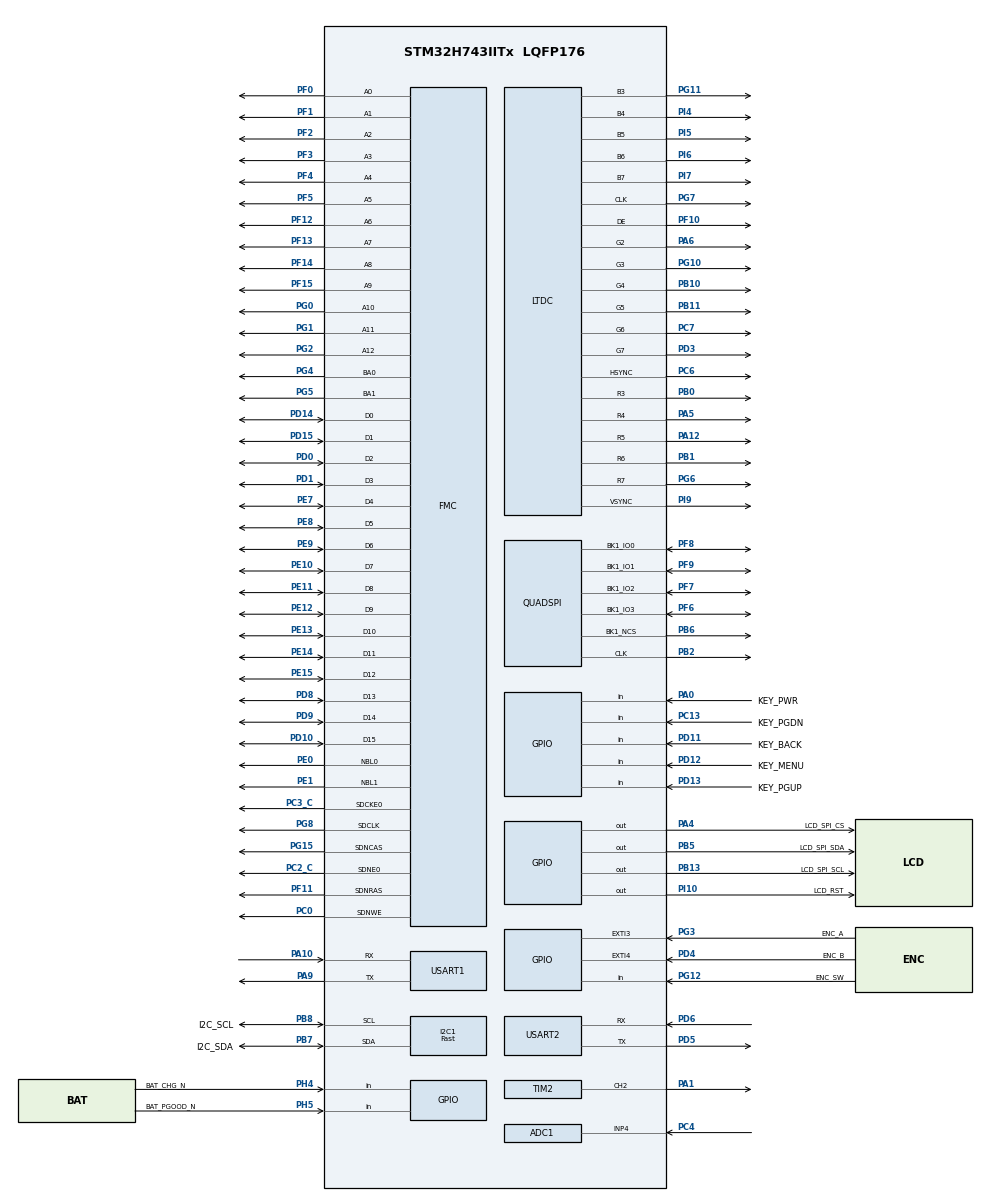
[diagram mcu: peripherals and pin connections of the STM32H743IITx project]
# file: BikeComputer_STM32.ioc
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ADC1.Channel-0\#ChannelRegularConversion=ADC_CHANNEL_4
ADC1.ClockPrescaler=ADC_CLOCK_ASYNC_DIV4
ADC1.NbrOfConversionFlag=1
ADC1.OffsetNumber-0\#ChannelRegularConversion=ADC_OFFSET_NONE
ADC1.OffsetSignedSaturation-0\#ChannelRegularConversion=DISABLE
ADC1.Rank-0\#ChannelRegularConversion=1
ADC1.SamplingTime-0\#ChannelRegularConversion=ADC_SAMPLETIME_387CYCLES_5
ADC1.master=1
CORTEX_M7.AccessPermission_S-Cortex_Memory_Protection_Unit_Region1_Settings_S=MPU_REGION_FULL_ACCESS
CORTEX_M7.AccessPermission_S-Cortex_Memory_Protection_Unit_Region2_Settings_S=MPU_REGION_FULL_ACCESS
CORTEX_M7.AccessPermission_S-Cortex_Memory_Protection_Unit_Region3_Settings_S=MPU_REGION_PRIV_RO_URO
CORTEX_M7.AccessPermission_Spec=MPU_REGION_NO_ACCESS
CORTEX_M7.BaseAddress_S-Cortex_Memory_Protection_Unit_Region1_Settings_S=0xC0000000
CORTEX_M7.BaseAddress_S-Cortex_Memory_Protection_Unit_Region2_Settings_S=0xC0000000
CORTEX_M7.BaseAddress_S-Cortex_Memory_Protection_Unit_Region3_Settings_S=0x90000000
CORTEX_M7.BaseAddress_Spec=0x00000000
CORTEX_M7.CPU_DCache=Enabled
CORTEX_M7.CPU_ICache=Enabled
CORTEX_M7.DisableExec_S-Cortex_Memory_Protection_Unit_Region1_Settings_S=MPU_INSTRUCTION_ACCESS_DISABLE
CORTEX_M7.DisableExec_S-Cortex_Memory_Protection_Unit_Region2_Settings_S=MPU_INSTRUCTION_ACCESS_DISABLE
CORTEX_M7.DisableExec_S-Cortex_Memory_Protection_Unit_Region3_Settings_S=MPU_INSTRUCTION_ACCESS_DISABLE
CORTEX_M7.Enable_S-Cortex_Memory_Protection_Unit_Region1_Settings_S=MPU_REGION_ENABLE
CORTEX_M7.Enable_S-Cortex_Memory_Protection_Unit_Region2_Settings_S=MPU_REGION_ENABLE
CORTEX_M7.Enable_S-Cortex_Memory_Protection_Unit_Region3_Settings_S=MPU_REGION_ENABLE
CORTEX_M7.IsBufferable_S-Cortex_Memory_Protection_Unit_Region1_Settings_S=MPU_ACCESS_BUFFERABLE
CORTEX_M7.IsBufferable_Spec=MPU_ACCESS_NOT_BUFFERABLE
CORTEX_M7.IsCacheable_S-Cortex_Memory_Protection_Unit_Region1_Settings_S=MPU_ACCESS_CACHEABLE
CORTEX_M7.IsCacheable_Spec=MPU_ACCESS_NOT_CACHEABLE
CORTEX_M7.IsShareable_Spec=MPU_ACCESS_SHAREABLE
CORTEX_M7.Size_S-Cortex_Memory_Protection_Unit_Region1_Settings_S=MPU_REGION_SIZE_32MB
CORTEX_M7.Size_S-Cortex_Memory_Protection_Unit_Region2_Settings_S=MPU_REGION_SIZE_2MB
CORTEX_M7.Size_S-Cortex_Memory_Protection_Unit_Region3_Settings_S=MPU_REGION_SIZE_16MB
CORTEX_M7.Size_Spec=MPU_REGION_SIZE_4GB
CORTEX_M7.SubRegionDisable_Spec=0x87
CORTEX_M7.TypeExtField_S-Cortex_Memory_Protection_Unit_Region2_Settings_S=MPU_TEX_LEVEL1
CORTEX_M7.TypeExtField_S-Cortex_Memory_Protection_Unit_Region3_Settings_S=MPU_TEX_LEVEL1
CORTEX_M7.default_mode_Activation=1
DMA2D.ColorMode=DMA2D_OUTPUT_RGB565
Dma.Request0=USART2_RX
Dma.USART2_RX.0.Direction=DMA_PERIPH_TO_MEMORY
Dma.USART2_RX.0.EventEnable=DISABLE
Dma.USART2_RX.0.FIFOMode=DMA_FIFOMODE_DISABLE
Dma.USART2_RX.0.Instance=DMA1_Stream0
Dma.USART2_RX.0.MemDataAlignment=DMA_MDATAALIGN_BYTE
Dma.USART2_RX.0.MemInc=DMA_MINC_ENABLE
Dma.USART2_RX.0.Mode=DMA_CIRCULAR
Dma.USART2_RX.0.PeriphDataAlignment=DMA_PDATAALIGN_BYTE
Dma.USART2_RX.0.PeriphInc=DMA_PINC_DISABLE
Dma.USART2_RX.0.Polarity=HAL_DMAMUX_REQ_GEN_RISING
Dma.USART2_RX.0.Priority=DMA_PRIORITY_HIGH
Dma.USART2_RX.0.RequestNumber=1
Dma.USART2_RX.0.SignalID=NONE
Dma.USART2_RX.0.SyncEnable=DISABLE
Dma.USART2_RX.0.SyncPolarity=HAL_DMAMUX_SYNC_NO_EVENT
Dma.USART2_RX.0.SyncRequestNumber=1
Dma.USART2_RX.0.SyncSignalID=NONE
FMC.CASLatency1=FMC_SDRAM_CAS_LATENCY_3
FMC.ColumnBitsNumber1=FMC_SDRAM_COLUMN_BITS_NUM_9
FMC.ExitSelfRefreshDelay1=8
FMC.LoadToActiveDelay1=2
FMC.RCDDelay1=2
FMC.RPDelay1=2
FMC.RPDelay2=2
FMC.ReadBurst1=FMC_SDRAM_RBURST_ENABLE
FMC.ReadBurst2=FMC_SDRAM_RBURST_ENABLE
FMC.ReadPipeDelay1=FMC_SDRAM_RPIPE_DELAY_1
FMC.ReadPipeDelay2=FMC_SDRAM_RPIPE_DELAY_1
FMC.RowCycleDelay1=6
FMC.RowCycleDelay2=6
FMC.SDClockPeriod1=FMC_SDRAM_CLOCK_PERIOD_2
FMC.SDClockPeriod2=FMC_SDRAM_CLOCK_PERIOD_2
FMC.SelfRefreshTime1=5
FMC.WriteRecoveryTime1=3
FREERTOS.Tasks01=defaultTask,24,128,StartDefaultTask,Default,NULL,Dynamic,NULL,NULL
I2C1.I2C_Fall_Time=20
I2C1.I2C_Rise_Time=200
I2C1.I2C_Speed_Mode=I2C_Fast
I2C1.Speed=400
I2C1.Timing=0x10E01A4F
LTDC.ActiveH=854
LTDC.ActiveW=480
LTDC.Alpha_L0=255
LTDC.FBStartAdress_L0=0xC0000000
LTDC.HBP=43
LTDC.HFP=8
LTDC.HSync=2
LTDC.ImageHeight_L0=854
LTDC.ImageWidth_L0=480
LTDC.Layers=0
LTDC.PCPolarity=LTDC_PCPOLARITY_IIPC
LTDC.PixelFormat_L0=LTDC_PIXEL_FORMAT_RGB565
LTDC.VBP=25
LTDC.VFP=15
LTDC.VSync=2
LTDC.WindowX1_L0=480
LTDC.WindowY1_L0=854
Mcu.Family=STM32H7
Mcu.Name=STM32H743IITx
Mcu.Package=LQFP176
NVIC.DMA1_Stream0_IRQn=true\:5\:0\:false\:false\:true\:true\:false\:true\:true
NVIC.DMA2D_IRQn=true\:5\:0\:false\:false\:true\:true\:true\:true\:true
NVIC.EXTI3_IRQn=true\:5\:0\:true\:false\:true\:true\:true\:true\:true
NVIC.EXTI4_IRQn=true\:5\:0\:false\:false\:true\:true\:true\:true\:true
NVIC.I2C1_ER_IRQn=true\:5\:0\:false\:false\:true\:true\:true\:true\:true
NVIC.I2C1_EV_IRQn=true\:5\:0\:false\:false\:true\:true\:true\:true\:true
NVIC.LTDC_ER_IRQn=true\:5\:0\:false\:false\:true\:true\:true\:true\:true
NVIC.LTDC_IRQn=true\:5\:0\:true\:false\:true\:true\:true\:true\:true
NVIC.PriorityGroup=NVIC_PRIORITYGROUP_4
NVIC.TIM6_DAC_IRQn=true\:15\:0\:false\:false\:true\:false\:false\:true\:true
NVIC.TimeBase=TIM6_DAC_IRQn
NVIC.TimeBaseIP=TIM6
NVIC.USART1_IRQn=true\:5\:0\:true\:false\:false\:false\:true\:true\:true
NVIC.USART2_IRQn=true\:5\:0\:false\:false\:true\:true\:true\:true\:true
PA0.GPIO_Label=KEY_PWR
PA0.GPIO_PuPd=GPIO_PULLUP
PA0.Signal=GPIO_Input
PA1.Signal=S_TIM2_CH2
PA10.Mode=Asynchronous
PA10.Signal=USART1_RX
PA12.GPIO_Speed=GPIO_SPEED_FREQ_VERY_HIGH
PA12.Mode=RGB565
PA12.Signal=LTDC_R5
PA13\ (JTMS/SWDIO).Mode=Serial_Wire
PA13\ (JTMS/SWDIO).Signal=DEBUG_JTMS-SWDIO
PA14\ (JTCK/SWCLK).Mode=Serial_Wire
PA14\ (JTCK/SWCLK).Signal=DEBUG_JTCK-SWCLK
PA4.GPIO_Label=LCD_SPI_CS
PA4.GPIO_Speed=GPIO_SPEED_FREQ_HIGH
PA4.Signal=GPIO_Output
PA5.GPIO_Speed=GPIO_SPEED_FREQ_VERY_HIGH
PA5.Mode=RGB565
PA5.Signal=LTDC_R4
PA6.GPIO_Speed=GPIO_SPEED_FREQ_VERY_HIGH
PA6.Mode=RGB565
PA6.Signal=LTDC_G2
PA9.Mode=Asynchronous
PA9.Signal=USART1_TX
PB0.GPIO_Speed=GPIO_SPEED_FREQ_VERY_HIGH
PB0.Mode=RGB565
PB0.Signal=LTDC_R3
PB1.GPIO_Speed=GPIO_SPEED_FREQ_VERY_HIGH
PB1.Mode=RGB565
PB1.Signal=LTDC_R6
PB10.GPIO_Speed=GPIO_SPEED_FREQ_VERY_HIGH
PB10.Mode=RGB565
PB10.Signal=LTDC_G4
PB11.GPIO_Speed=GPIO_SPEED_FREQ_VERY_HIGH
PB11.Mode=RGB565
PB11.Signal=LTDC_G5
PB13.GPIO_Label=LCD_SPI_SCL
PB13.Signal=GPIO_Output
PB2.GPIO_Speed=GPIO_SPEED_FREQ_VERY_HIGH
PB2.Mode=Single Bank 1
PB2.Signal=QUADSPI_CLK
PB5.GPIO_Label=LCD_SPI_SDA
PB5.GPIO_Speed=GPIO_SPEED_FREQ_HIGH
PB5.Signal=GPIO_Output
PB6.GPIO_Speed=GPIO_SPEED_FREQ_VERY_HIGH
PB6.Mode=Single Bank 1
PB6.Signal=QUADSPI_BK1_NCS
PB7.GPIO_Label=I2C_SDA
PB7.Mode=I2C
PB7.Signal=I2C1_SDA
PB8.GPIO_Label=I2C_SCL
PB8.Mode=I2C
PB8.Signal=I2C1_SCL
PC0.Signal=FMC_SDNWE
PC13.GPIO_Label=KEY_PGDN
PC13.GPIO_PuPd=GPIO_PULLUP
PC13.Signal=GPIO_Input
PC14-OSC32_IN\ (OSC32_IN).Mode=LSE-External-Oscillator
PC14-OSC32_IN\ (OSC32_IN).Signal=RCC_OSC32_IN
PC15-OSC32_OUT\ (OSC32_OUT).Mode=LSE-External-Oscillator
PC15-OSC32_OUT\ (OSC32_OUT).Signal=RCC_OSC32_OUT
PC2_C.Mode=SdramChipSelect1_1
PC2_C.Signal=FMC_SDNE0
PC3_C.Mode=SdramChipSelect1_1
PC3_C.Signal=FMC_SDCKE0
PC4.Signal=ADCx_INP4
PC6.GPIO_Speed=GPIO_SPEED_FREQ_VERY_HIGH
PC6.Mode=RGB565
PC6.Signal=LTDC_HSYNC
PC7.GPIO_Speed=GPIO_SPEED_FREQ_VERY_HIGH
PC7.Mode=RGB565
PC7.Signal=LTDC_G6
PD0.Signal=FMC_D2_DA2
PD1.Signal=FMC_D3_DA3
PD10.Signal=FMC_D15_DA15
PD11.GPIO_Label=KEY_BACK
PD11.GPIO_PuPd=GPIO_PULLUP
PD11.Signal=GPIO_Input
PD12.GPIO_Label=KEY_MENU
PD12.GPIO_PuPd=GPIO_PULLUP
PD12.Signal=GPIO_Input
PD13.GPIO_Label=KEY_PGUP
PD13.GPIO_PuPd=GPIO_PULLUP
PD13.Signal=GPIO_Input
PD14.Signal=FMC_D0_DA0
PD15.Signal=FMC_D1_DA1
PD3.GPIO_Speed=GPIO_SPEED_FREQ_VERY_HIGH
PD3.Mode=RGB565
PD3.Signal=LTDC_G7
PD4.GPIO_Label=ENC_B
PD4.GPIO_ModeDefaultEXTI=GPIO_MODE_IT_RISING_FALLING
PD4.GPIO_PuPd=GPIO_PULLUP
PD4.Signal=GPXTI4
PD5.GPIO_ModeDefaultPP=GPIO_MODE_AF_PP
PD5.Mode=Asynchronous
PD5.Signal=USART2_TX
PD6.Mode=Asynchronous
PD6.Signal=USART2_RX
PD8.Signal=FMC_D13_DA13
PD9.Signal=FMC_D14_DA14
PE0.Signal=FMC_NBL0
PE1.Signal=FMC_NBL1
PE10.Signal=FMC_D7_DA7
PE11.Signal=FMC_D8_DA8
PE12.Signal=FMC_D9_DA9
PE13.Signal=FMC_D10_DA10
PE14.Signal=FMC_D11_DA11
PE15.Signal=FMC_D12_DA12
PE7.Signal=FMC_D4_DA4
PE8.Signal=FMC_D5_DA5
PE9.Signal=FMC_D6_DA6
PF0.Signal=FMC_A0
PF1.Signal=FMC_A1
PF10.GPIO_Speed=GPIO_SPEED_FREQ_VERY_HIGH
PF10.Mode=RGB565
PF10.Signal=LTDC_DE
PF11.Signal=FMC_SDNRAS
PF12.Signal=FMC_A6
PF13.Signal=FMC_A7
PF14.Signal=FMC_A8
PF15.Signal=FMC_A9
PF2.Signal=FMC_A2
PF3.Signal=FMC_A3
PF4.Signal=FMC_A4
PF5.Signal=FMC_A5
PF6.GPIO_Speed=GPIO_SPEED_FREQ_VERY_HIGH
PF6.Mode=Single Bank 1
PF6.Signal=QUADSPI_BK1_IO3
PF7.GPIO_Speed=GPIO_SPEED_FREQ_VERY_HIGH
PF7.Mode=Single Bank 1
PF7.Signal=QUADSPI_BK1_IO2
PF8.GPIO_Speed=GPIO_SPEED_FREQ_VERY_HIGH
PF8.Mode=Single Bank 1
PF8.Signal=QUADSPI_BK1_IO0
PF9.GPIO_Speed=GPIO_SPEED_FREQ_VERY_HIGH
PF9.Mode=Single Bank 1
PF9.Signal=QUADSPI_BK1_IO1
PG0.Signal=FMC_A10
PG1.Signal=FMC_A11
PG10.GPIO_Speed=GPIO_SPEED_FREQ_VERY_HIGH
PG10.Mode=RGB565
PG10.Signal=LTDC_G3
PG11.GPIO_Speed=GPIO_SPEED_FREQ_VERY_HIGH
PG11.Mode=RGB565
PG11.Signal=LTDC_B3
PG12.GPIO_Label=ENC_SW
PG12.GPIO_PuPd=GPIO_PULLUP
PG12.Signal=GPIO_Input
PG15.Signal=FMC_SDNCAS
PG2.Signal=FMC_A12
PG3.GPIO_Label=ENC_A
PG3.GPIO_ModeDefaultEXTI=GPIO_MODE_IT_RISING_FALLING
PG3.GPIO_PuPd=GPIO_PULLUP
PG3.Signal=GPXTI3
PG4.Signal=FMC_A14_BA0
PG5.Signal=FMC_A15_BA1
PG6.GPIO_Speed=GPIO_SPEED_FREQ_VERY_HIGH
PG6.Mode=RGB565
PG6.Signal=LTDC_R7
PG7.GPIO_Speed=GPIO_SPEED_FREQ_VERY_HIGH
PG7.Mode=RGB565
PG7.Signal=LTDC_CLK
PG8.Signal=FMC_SDCLK
PH0-OSC_IN\ (PH0).Mode=HSE-External-Oscillator
PH0-OSC_IN\ (PH0).Signal=RCC_OSC_IN
PH1-OSC_OUT\ (PH1).Mode=HSE-External-Oscillator
PH1-OSC_OUT\ (PH1).Signal=RCC_OSC_OUT
PH4.GPIO_Label=BAT_CHG_N
PH4.Signal=GPIO_Input
PH5.GPIO_Label=BAT_PGOOD_N
PH5.Signal=GPIO_Input
PI10.GPIO_Label=LCD_RST
PI10.GPIO_Speed=GPIO_SPEED_FREQ_HIGH
PI10.Signal=GPIO_Output
PI4.GPIO_Speed=GPIO_SPEED_FREQ_VERY_HIGH
PI4.Mode=RGB565
PI4.Signal=LTDC_B4
PI5.GPIO_Speed=GPIO_SPEED_FREQ_VERY_HIGH
PI5.Mode=RGB565
PI5.Signal=LTDC_B5
PI6.GPIO_Speed=GPIO_SPEED_FREQ_VERY_HIGH
PI6.Mode=RGB565
PI6.Signal=LTDC_B6
PI7.GPIO_Speed=GPIO_SPEED_FREQ_VERY_HIGH
PI7.Mode=RGB565
PI7.Signal=LTDC_B7
PI9.GPIO_Speed=GPIO_SPEED_FREQ_VERY_HIGH
PI9.Mode=RGB565
PI9.Signal=LTDC_VSYNC
ProjectManager.HeapSize=0x2000
ProjectManager.StackSize=0x1000
ProjectManager.TargetToolchain=MDK-ARM V5
QUADSPI.ChipSelectHighTime=QSPI_CS_HIGH_TIME_4_CYCLE
QUADSPI.ClockPrescaler=7
QUADSPI.FifoThreshold=4
QUADSPI.FlashSize=23
QUADSPI.SampleShifting=QSPI_SAMPLE_SHIFTING_HALFCYCLE
RCC.ADCCLockSelection=RCC_ADCCLKSOURCE_CLKP
RCC.ADCFreq_Value=64000000
RCC.APB1Freq_Value=100000000
RCC.APB2Freq_Value=100000000
RCC.APB3Freq_Value=100000000
RCC.APB4Freq_Value=100000000
RCC.CortexFreq_Value=400000000
RCC.D1PPRE=RCC_APB3_DIV2
RCC.D2PPRE1=RCC_APB1_DIV2
RCC.D2PPRE2=RCC_APB2_DIV2
RCC.D3PPRE=RCC_APB4_DIV2
RCC.DIVM1=5
RCC.DIVM3=5
RCC.DIVN1=160
RCC.DIVN3=149
RCC.DIVR3=26
RCC.HCLKFreq_Value=200000000
RCC.HPRE=RCC_HCLK_DIV2
RCC.PLLFRACN=0
RCC.PLLSourceVirtual=RCC_PLLSOURCE_HSE
RCC.PWR_Regulator_Voltage_Scale=PWR_REGULATOR_VOLTAGE_SCALE1
RCC.SYSCLKFreq_VALUE=400000000
RCC.SYSCLKSource=RCC_SYSCLKSOURCE_PLLCLK
RCC.USBFreq_Value=400000000
SH.ADCx_INP4.0=ADC1_INP4,IN4-Single-Ended
SH.FMC_A0.0=FMC_A0,13b-sda1
SH.FMC_A1.0=FMC_A1,13b-sda1
SH.FMC_A10.0=FMC_A10,13b-sda1
SH.FMC_A11.0=FMC_A11,13b-sda1
SH.FMC_A12.0=FMC_A12,13b-sda1
SH.FMC_A14_BA0.0=FMC_BA0,FourSdramBanks1
SH.FMC_A15_BA1.0=FMC_BA1,FourSdramBanks1
SH.FMC_A2.0=FMC_A2,13b-sda1
SH.FMC_A3.0=FMC_A3,13b-sda1
SH.FMC_A4.0=FMC_A4,13b-sda1
SH.FMC_A5.0=FMC_A5,13b-sda1
SH.FMC_A6.0=FMC_A6,13b-sda1
SH.FMC_A7.0=FMC_A7,13b-sda1
SH.FMC_A8.0=FMC_A8,13b-sda1
SH.FMC_A9.0=FMC_A9,13b-sda1
SH.FMC_D0_DA0.0=FMC_D0,sd-16b-d1
SH.FMC_D10_DA10.0=FMC_D10,sd-16b-d1
SH.FMC_D11_DA11.0=FMC_D11,sd-16b-d1
SH.FMC_D12_DA12.0=FMC_D12,sd-16b-d1
SH.FMC_D13_DA13.0=FMC_D13,sd-16b-d1
SH.FMC_D14_DA14.0=FMC_D14,sd-16b-d1
SH.FMC_D15_DA15.0=FMC_D15,sd-16b-d1
SH.FMC_D1_DA1.0=FMC_D1,sd-16b-d1
SH.FMC_D2_DA2.0=FMC_D2,sd-16b-d1
SH.FMC_D3_DA3.0=FMC_D3,sd-16b-d1
SH.FMC_D4_DA4.0=FMC_D4,sd-16b-d1
SH.FMC_D5_DA5.0=FMC_D5,sd-16b-d1
SH.FMC_D6_DA6.0=FMC_D6,sd-16b-d1
SH.FMC_D7_DA7.0=FMC_D7,sd-16b-d1
SH.FMC_D8_DA8.0=FMC_D8,sd-16b-d1
SH.FMC_D9_DA9.0=FMC_D9,sd-16b-d1
SH.FMC_NBL0.0=FMC_NBL0,Sd2ByteEnable1
SH.FMC_NBL1.0=FMC_NBL1,Sd2ByteEnable1
SH.FMC_SDCLK.0=FMC_SDCLK,13b-sda1
SH.FMC_SDNCAS.0=FMC_SDNCAS,13b-sda1
SH.FMC_SDNRAS.0=FMC_SDNRAS,13b-sda1
SH.FMC_SDNWE.0=FMC_SDNWE,13b-sda1
SH.S_TIM2_CH2.0=TIM2_CH2,PWM Generation2 CH2
TIM2.AutoReloadPreload=TIM_AUTORELOAD_PRELOAD_ENABLE
TIM2.Channel-PWM\ Generation2\ CH2=TIM_CHANNEL_2
TIM2.Period=1000-1
TIM2.Prescaler=200-1
USART1.VirtualMode-Asynchronous=VM_ASYNC
USART2.VirtualMode-Asynchronous=VM_ASYNC
VP_DMA2D_VS_DMA2D.Mode=DMA2D_Activate
VP_FREERTOS_VS_CMSIS_V2.Mode=CMSIS_V2
VP_MEMORYMAP_VS_MEMORYMAP.Mode=CurAppReg
VP_SYS_VS_tim6.Mode=TIM6
VP_TIM2_VS_ClockSourceINT.Mode=Internal
board=custom

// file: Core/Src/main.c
/* USER CODE BEGIN Header */
/**
  ******************************************************************************
  * @file           : main.c
  * @brief          : Main program body
  ******************************************************************************
  * @attention
  *
  * Copyright (c) 2026 STMicroelectronics.
  * All rights reserved.
  *
  * This software is licensed under terms that can be found in the LICENSE file
  * in the root directory of this software component.
  * If no LICENSE file comes with this software, it is provided AS-IS.
  *
  ******************************************************************************
  */
/* USER CODE END Header */
#include "main.h"
#include "cmsis_os.h"
#include "adc.h"
#include "dma.h"
#include "dma2d.h"
#include "i2c.h"
#include "quadspi.h"
#include "tim.h"
#include "usart.h"
#include "gpio.h"

/* USER CODE BEGIN Includes */
#include "app_main.h"
#include "bsp_qspi.h" /* 资源映射基址由 BSP 统一定义。 */
/* USER CODE END Includes */

void SystemClock_Config(void);
void PeriphCommonClock_Config(void);
static void MPU_Config(void);
void MX_FREERTOS_Init(void);

int main(void)
{

  /* MPU Configuration--------------------------------------------------------*/
  MPU_Config();

  /* Enable the CPU Cache */

  /* Enable I-Cache---------------------------------------------------------*/
  SCB_EnableICache();

  /* Enable D-Cache---------------------------------------------------------*/
  SCB_EnableDCache();

  /* MCU Configuration--------------------------------------------------------*/

  /* Reset of all peripherals, Initializes the Flash interface and the Systick. */
  HAL_Init();

  /* Configure the system clock */
  SystemClock_Config();

  /* Configure the peripherals common clocks */
  PeriphCommonClock_Config();

  /* Initialize all configured peripherals */
  MX_GPIO_Init();
  MX_DMA_Init();
  MX_USART1_UART_Init();
  MX_USART2_UART_Init();
  MX_I2C1_Init();
  MX_TIM2_Init();
  MX_DMA2D_Init();
  MX_QUADSPI_Init();
  MX_ADC1_Init();
  /* USER CODE BEGIN 2 */
  App_Main();

  /* USER CODE END 2 */

  /* Init scheduler */
  osKernelInitialize();  /* Call init function for freertos objects (in cmsis_os2.c) */
  MX_FREERTOS_Init();

  /* Start scheduler */
  osKernelStart();

  /* We should never get here as control is now taken by the scheduler */

  /* Infinite loop */
  while (1)
  {

  }
}

void SystemClock_Config(void)
{
  RCC_OscInitTypeDef RCC_OscInitStruct = {0};
  RCC_ClkInitTypeDef RCC_ClkInitStruct = {0};

  /** Supply configuration update enable
  */
  HAL_PWREx_ConfigSupply(PWR_LDO_SUPPLY);

  /** Configure the main internal regulator output voltage
  */
  __HAL_PWR_VOLTAGESCALING_CONFIG(PWR_REGULATOR_VOLTAGE_SCALE1);

  while(!__HAL_PWR_GET_FLAG(PWR_FLAG_VOSRDY)) {}

  /** Initializes the RCC Oscillators according to the specified parameters
  * in the RCC_OscInitTypeDef structure.
  */
  RCC_OscInitStruct.OscillatorType = RCC_OSCILLATORTYPE_HSI|RCC_OSCILLATORTYPE_HSE;
  RCC_OscInitStruct.HSEState = RCC_HSE_ON;
  RCC_OscInitStruct.HSIState = RCC_HSI_DIV1;
  RCC_OscInitStruct.HSICalibrationValue = RCC_HSICALIBRATION_DEFAULT;
  RCC_OscInitStruct.PLL.PLLState = RCC_PLL_ON;
  RCC_OscInitStruct.PLL.PLLSource = RCC_PLLSOURCE_HSE;
  RCC_OscInitStruct.PLL.PLLM = 5;
  RCC_OscInitStruct.PLL.PLLN = 160;
  RCC_OscInitStruct.PLL.PLLP = 2;
  RCC_OscInitStruct.PLL.PLLQ = 2;
  RCC_OscInitStruct.PLL.PLLR = 2;
  RCC_OscInitStruct.PLL.PLLRGE = RCC_PLL1VCIRANGE_2;
  RCC_OscInitStruct.PLL.PLLVCOSEL = RCC_PLL1VCOWIDE;
  RCC_OscInitStruct.PLL.PLLFRACN = 0;
  if (HAL_RCC_OscConfig(&RCC_OscInitStruct) != HAL_OK)
  {
    Error_Handler();
  }

  /** Initializes the CPU, AHB and APB buses clocks
  */
  RCC_ClkInitStruct.ClockType = RCC_CLOCKTYPE_HCLK|RCC_CLOCKTYPE_SYSCLK
                              |RCC_CLOCKTYPE_PCLK1|RCC_CLOCKTYPE_PCLK2
                              |RCC_CLOCKTYPE_D3PCLK1|RCC_CLOCKTYPE_D1PCLK1;
  RCC_ClkInitStruct.SYSCLKSource = RCC_SYSCLKSOURCE_PLLCLK;
  RCC_ClkInitStruct.SYSCLKDivider = RCC_SYSCLK_DIV1;
  RCC_ClkInitStruct.AHBCLKDivider = RCC_HCLK_DIV2;
  RCC_ClkInitStruct.APB3CLKDivider = RCC_APB3_DIV2;
  RCC_ClkInitStruct.APB1CLKDivider = RCC_APB1_DIV2;
  RCC_ClkInitStruct.APB2CLKDivider = RCC_APB2_DIV2;
  RCC_ClkInitStruct.APB4CLKDivider = RCC_APB4_DIV2;

  if (HAL_RCC_ClockConfig(&RCC_ClkInitStruct, FLASH_LATENCY_2) != HAL_OK)
  {
    Error_Handler();
  }
}

void PeriphCommonClock_Config(void)
{
  RCC_PeriphCLKInitTypeDef PeriphClkInitStruct = {0};

  /** Initializes the peripherals clock
  */
  PeriphClkInitStruct.PeriphClockSelection = RCC_PERIPHCLK_CKPER;
  PeriphClkInitStruct.CkperClockSelection = RCC_CLKPSOURCE_HSI;
  if (HAL_RCCEx_PeriphCLKConfig(&PeriphClkInitStruct) != HAL_OK)
  {
    Error_Handler();
  }
}

 /* MPU Configuration */

void MPU_Config(void)
{
  MPU_Region_InitTypeDef MPU_InitStruct = {0};

  /* Disables the MPU */
  HAL_MPU_Disable();

  /** Initializes and configures the Region and the memory to be protected
  */
  MPU_InitStruct.Enable = MPU_REGION_ENABLE;
  MPU_InitStruct.Number = MPU_REGION_NUMBER0;
  MPU_InitStruct.BaseAddress = 0x00000000;
  MPU_InitStruct.Size = MPU_REGION_SIZE_4GB;
  MPU_InitStruct.SubRegionDisable = 0x87;
  MPU_InitStruct.TypeExtField = MPU_TEX_LEVEL0;
  MPU_InitStruct.AccessPermission = MPU_REGION_NO_ACCESS;
  MPU_InitStruct.DisableExec = MPU_INSTRUCTION_ACCESS_DISABLE;
  MPU_InitStruct.IsShareable = MPU_ACCESS_SHAREABLE;
  MPU_InitStruct.IsCacheable = MPU_ACCESS_NOT_CACHEABLE;
  MPU_InitStruct.IsBufferable = MPU_ACCESS_NOT_BUFFERABLE;

  HAL_MPU_ConfigRegion(&MPU_InitStruct);

  /** Initializes and configures the Region and the memory to be protected
  */
  MPU_InitStruct.Number = MPU_REGION_NUMBER1;
  MPU_InitStruct.BaseAddress = 0xC0000000;
  MPU_InitStruct.Size = MPU_REGION_SIZE_32MB;
  MPU_InitStruct.SubRegionDisable = 0x0;
  MPU_InitStruct.AccessPermission = MPU_REGION_FULL_ACCESS;
  MPU_InitStruct.IsShareable = MPU_ACCESS_NOT_SHAREABLE;
  MPU_InitStruct.IsCacheable = MPU_ACCESS_CACHEABLE;
  MPU_InitStruct.IsBufferable = MPU_ACCESS_BUFFERABLE;

  HAL_MPU_ConfigRegion(&MPU_InitStruct);

  /** Initializes and configures the Region and the memory to be protected
  */
  MPU_InitStruct.Number = MPU_REGION_NUMBER2;
  MPU_InitStruct.Size = MPU_REGION_SIZE_2MB;
  MPU_InitStruct.TypeExtField = MPU_TEX_LEVEL1;
  MPU_InitStruct.IsCacheable = MPU_ACCESS_NOT_CACHEABLE;
  MPU_InitStruct.IsBufferable = MPU_ACCESS_NOT_BUFFERABLE;

  HAL_MPU_ConfigRegion(&MPU_InitStruct);

  /** Initializes and configures the Region and the memory to be protected
  */
  MPU_InitStruct.Number = MPU_REGION_NUMBER3;
  MPU_InitStruct.BaseAddress = 0x90000000;
  MPU_InitStruct.Size = MPU_REGION_SIZE_16MB;
  MPU_InitStruct.AccessPermission = MPU_REGION_PRIV_RO_URO;

  HAL_MPU_ConfigRegion(&MPU_InitStruct);
  /* Enables the MPU */
  HAL_MPU_Enable(MPU_PRIVILEGED_DEFAULT);

}

void HAL_TIM_PeriodElapsedCallback(TIM_HandleTypeDef *htim)
{
  if (htim->Instance == TIM6)
  {
    HAL_IncTick();
  }
}

void Error_Handler(void)
{
  __disable_irq();
  while (1)
  {
  }
}

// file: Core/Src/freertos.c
/* USER CODE BEGIN Header */
/**
  ******************************************************************************
  * File Name          : freertos.c
  * Description        : Code for freertos applications
  ******************************************************************************
  * @attention
  *
  * Copyright (c) 2026 STMicroelectronics.
  * All rights reserved.
  *
  * This software is licensed under terms that can be found in the LICENSE file
  * in the root directory of this software component.
  * If no LICENSE file comes with this software, it is provided AS-IS.
  *
  ******************************************************************************
  */
/* USER CODE END Header */

#include "FreeRTOS.h"
#include "task.h"
#include "main.h"
#include "cmsis_os.h"

/* USER CODE BEGIN Includes */
#include "app_rtos.h"
/* USER CODE END Includes */

/* Definitions for defaultTask */
osThreadId_t defaultTaskHandle;
const osThreadAttr_t defaultTask_attributes = {
  .name = "defaultTask",
  .stack_size = 128 * 4,
  .priority = (osPriority_t) osPriorityNormal,
};

void StartDefaultTask(void *argument);

void MX_FREERTOS_Init(void); /* (MISRA C 2004 rule 8.1) */

void MX_FREERTOS_Init(void) {

  /* Create the thread(s) */
  /* creation of defaultTask */
  defaultTaskHandle = osThreadNew(StartDefaultTask, NULL, &defaultTask_attributes);

  /* USER CODE BEGIN RTOS_THREADS */
      App_RTOS_Init();
  /* add threads, ... */
  /* USER CODE END RTOS_THREADS */

}

void StartDefaultTask(void *argument)
{
  for(;;)
  {
    osDelay(1);
  }
}
